# gcr_me16 register map
Registers are access not given, no defined reset value unless marked. A register's access mark holds for its fields unless they carry their own. Offsets are from the block's base; lines under a group give offsets from that group; [hi:lo] are bit positions; {n}, {i} and the like mark numbered series; 'fields as' and 'values as' point back to an identical list; <NAME> marks a mode.

## Memory map
0x40000000 GCR size 0x400 — Global Control Registers.

## GCR — Global Control Registers.
Base 0x40000000
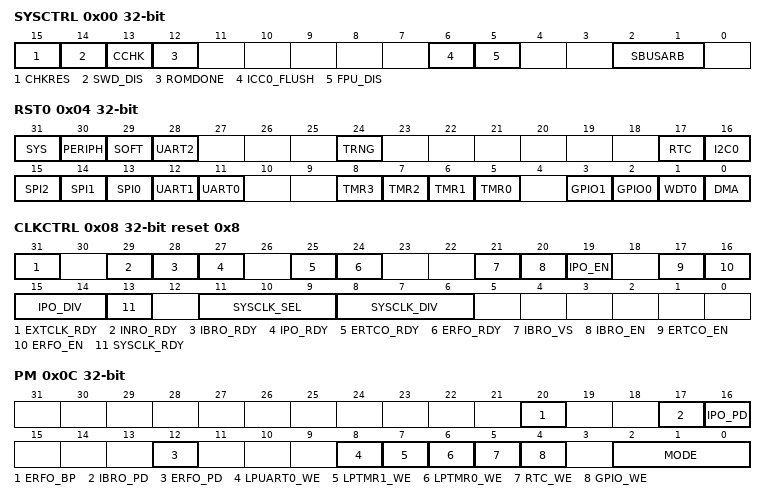
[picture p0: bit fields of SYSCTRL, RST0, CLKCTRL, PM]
0x00 SYSCTRL — System Control.
  [15] CHKRES — ROM Checksum Result. This bit is only valid when CHKRD=1.
    0=pass (ROM Checksum Correct.); 1=fail (ROM Checksum Fail.)
  [14] SWD_DIS — Serial Wire Debug Disable. This bit is used to disable the serial wire debug interface This bit is only writeable if (FMV lock word is not programmed) or if (ICE lock word is not programmed and the ROM_DONE bit is not set)
  [13] CCHK — Compute ROM Checksum. This bit is self-cleared when calculation is completed. Once set, software clearing this bit is ignored and the bit will remain set until the operation is completed.
    0=complete (No operation/complete.); 1=Start operation
  [12] ROMDONE — ROM_DONE status. Used to disable SWD interface during system initialization procedure
  [6] ICC0_FLUSH — Code Cache Flush. This bit is used to flush the code caches and the instruction buffer of the Cortex-M4.
    0=Normal Code Cache Operation; 1=flush (Code Caches and CPU instruction buffer are flushed)
  [5] FPU_DIS — Cortex M4 Floating Point Disable This bit is used to disable the floating-point unit of the Cortex-M4
  [2:1] SBUSARB — System bus abritration scheme. These bits are used to select between Fixed-burst abritration and Round-Robin scheme. The Round-Robin scheme is selected by default. These bits are reset by the system reset.
    0=fix (Fixed Burst abritration.); 1=Round-robin scheme
0x04 RST0 — Reset.
  [all] fields
    0=reset_done (Reset complete.); 1=busy (Starts Reset or indicates reset in progress.)
  [31] SYS — System Reset. Setting this bit to 1 resets the CPU core and all peripherals, including the watchdog timer.
  [30] PERIPH — Peripheral Reset. Setting this bit to 1 resets all peripherals. The CPU core, the watchdog timer, and all GPIO pins are unaffected by this reset.
  [29] SOFT — Soft Reset. Setting this bit to 1 resets everything except the CPU and the watchdog timer.
  [28] UART2 — UART2 Reset. Setting this bit to 1 resets all UART 2 blocks.
  [24] TRNG — TRNG Reset.
  [17] RTC — Real Time Clock Reset.
  [16] I2C0 — I2C0 Reset.
  [15] SPI2 — SPI2 Reset. Setting this bit to 1 resets all SPI 2 blocks.
  [14] SPI1 — SPI1 Reset. Setting this bit to 1 resets all SPI 1 blocks.
  [13] SPI0 — SPI0 Reset. Setting this bit to 1 resets all SPI 0 blocks.
  [12] UART1 — UART1 Reset. Setting this bit to 1 resets all UART 1 blocks.
  [11] UART0 — UART0 Reset. Setting this bit to 1 resets all UART 0 blocks.
  [n+5] TMR{n} (n=0..3) — Timer{n} Reset. Setting this bit to 1 resets Timer {n} blocks.
  [3] GPIO1 — GPIO1 Reset. Setting this bit to 1 resets GPIO1 pins to their default states.
  [2] GPIO0 — GPIO0 Reset. Setting this bit to 1 resets GPIO0 pins to their default states.
  [1] WDT0 — Watchdog Timer Reset.
  [0] DMA — DMA Reset.
0x08 CLKCTRL reset 0x8 — Clock Control.
  [31] EXTCLK_RDY ro — External Clock (GPIO0[11] AF2)
    0=not (Is not Ready.); 1=ready (Is Ready.)
  [29] INRO_RDY ro — 8kHz Low Frequency Reference Clock Ready.
    0=not (Is not Ready.); 1=ready (Is Ready.)
  [28] IBRO_RDY ro — 8MHz HIRC Ready.
    0=not (Is not Ready.); 1=ready (Is Ready.)
  [27] IPO_RDY ro — 96MHz HIRC Ready.
    0=not (Is not Ready.); 1=ready (Is Ready.)
  [25] ERTCO_RDY ro — 32kHz Crystal Oscillator Ready
    0=not (Is not Ready.); 1=ready (Is Ready.)
  [24] ERFO_RDY ro — 32MHz Crystal Oscillator Ready
    0=not (Is not Ready.); 1=ready (Is Ready.)
  [21] IBRO_VS — 8MHz High Frequency Internal Reference Clock Voltage Select. This register bit is used to select the power supply to the HIRC8M.
    0=VCore Supply; 1=1V (Dedicated 1v regulated supply.)
  [20] IBRO_EN — 8MHz High Frequency Internal Reference Clock Enable.
    0=dis (Is Disabled.); 1=en (Is Enabled.)
  [19] IPO_EN — 96MHz High Frequency Internal Reference Clock Enable.
    0=dis (Is Disabled.); 1=en (Is Enabled.)
  [17] ERTCO_EN — 32kHz Crystal Oscillator Enable.
    0=dis (Is Disabled.); 1=en (Is Enabled.)
  [16] ERFO_EN — 32MHz Crystal Oscillator Enable.
    0=dis (Is Disabled.); 1=en (Is Enabled.)
  [15:14] IPO_DIV — Divides the HIRC96M clock before the system clock prescaler, will affect HIRC96M Autocalibration.
    0=div1 (divide clock by 1); 1=div2 (divide clock by 2); 2=div4 (divide clock by 4); 3=div8 (divide clock by 8)
  [13] SYSCLK_RDY ro — Clock Ready. This read only bit reflects whether the currently selected system clock source is running.
    0=busy (Switchover to the new clock source (as selected by CLKSEL) has not yet occurred.); 1=ready (System clock running from CLKSEL clock source.)
  [11:9] SYSCLK_SEL — Clock Source Select. This 3 bit field selects the source for the system clock.
    2=ERFO (32MHz Crystal is used for the system clock.); 3=INRO (80kHz LIRC is used for the system clock.); 4=IPO (The internal 96 MHz oscillator is used for the system clock.); 5=IBRO (The internal 8 MHz oscillator is used for the system clock.); 6=ERTCO (32kHz is used for the system clock.); 7=EXTCLK (External clock on gpio0 11.)
  [8:6] SYSCLK_DIV — Prescaler Select. This 3 bit field sets the system operating frequency by controlling the prescaler that divides the output of the PLL0.
    0=div1 (Divide by 1.); 1=div2 (Divide by 2.); 2=div4 (Divide by 4.); 3=div8 (Divide by 8.); 4=div16 (Divide by 16.); 5=div32 (Divide by 32.); 6=div64 (Divide by 64.); 7=div128 (Divide by 128.)
0x0C PM — Power Management.
  [20] ERFO_BP — 32MHz Oscillator Bypass
  [17] IBRO_PD — 8MHz power down. This bit selects 8MHz HIRC power state in DEEPSLEEP mode.
    0=active (Mode is Active.); 1=deepsleep (Powered down in DEEPSLEEP.)
  [16] IPO_PD — 96MHz power down. This bit selects 96MHz HIRC power state in DEEPSLEEP mode.
    values as IBRO_PD
  [12] ERFO_PD — 32MHz power down. This bit selects 32MHz Crystal power state in DEEPSLEEP mode.
    values as IBRO_PD
  [8] LPUART0_WE — LPUART3 Wake Up Enable. This bit enables LPUART3 as wakeup source.
    0=dis (Wake Up Disable.); 1=en (Wake Up Enable.)
  [7] LPTMR1_WE — TIMER5 Wake Up Enable. This bit enables TIMER5 as wakeup source.
    0=dis (Wake Up Disable.); 1=en (Wake Up Enable.)
  [6] LPTMR0_WE — TIMER4 Wake Up Enable. This bit enables TIMER4 as wakeup source.
    0=dis (Wake Up Disable.); 1=en (Wake Up Enable.)
  [5] RTC_WE — RTC Alarm Wake Up Enable. This bit enables RTC alarm as wakeup source. If enabled, the desired RTC alarm must be configured via the RTC control registers.
    0=dis (Wake Up Disable.); 1=en (Wake Up Enable.)
  [4] GPIO_WE — GPIO Wake Up Enable. This bit enables all GPIO pins as potential wakeup sources. Any GPIO configured for wakeup is capable of causing an exit from IDLE or STANDBY modes when this bit is set.
    0=dis (Wake Up Disable.); 1=en (Wake Up Enable.)
  [2:0] MODE — Operating Mode. This two bit field selects the current operating mode for the device. Note that code execution only occurs during ACTIVE mode.
    0=Active Mode; 3=Shutdown Mode; 4=Backup Mode
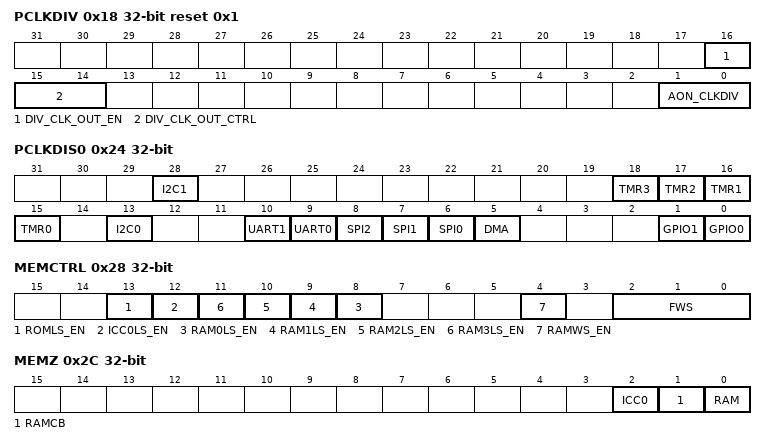
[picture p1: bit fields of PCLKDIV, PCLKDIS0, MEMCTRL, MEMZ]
0x18 PCLKDIV reset 0x1 — Peripheral Clock Divider.
  [16] DIV_CLK_OUT_EN — DIV_CLK_OUT Enable
  [15:14] DIV_CLK_OUT_CTRL — DIV_CLK_OUT Control
  [1:0] AON_CLKDIV — Always-ON (AON) domain Clock Divider. These bits define the AON domain clock divider
    0=div4; 1=div8; 2=div16; 3=div32
0x24 PCLKDIS0 — Peripheral Clock Disable.
  [all] fields
    0=en (enable it.); 1=dis (disable it.)
  [28] I2C1 — I2C 1 Disable.
  [n+15] TMR{n} (n=0..3) — Timer {n} Disable.
  [13] I2C0 — I2C 0 Disable.
  [10] UART1 — UART 1 Disable.
  [9] UART0 — UART 0 Disable.
  [8] SPI2 — SPI 2 Disable.
  [7] SPI1 — SPI 1 Disable.
  [6] SPI0 — SPI 0 Disable.
  [5] DMA — DMA Disable.
  [1] GPIO1 — GPIO1 Disable.
  [0] GPIO0 — GPIO0 Disable.
0x28 MEMCTRL — Memory Clock Control Register.
  [13] ROMLS_EN — ROM Light Sleep Mode.
    0=active (RAM is active.); 1=light_sleep (RAM is in Light Sleep mode.)
  [12] ICC0LS_EN — ICache RAM Light Sleep Mode.
    values as ROMLS_EN
  [n+8] RAM{n}LS_EN (n=0..3) — System RAM {n} Light Sleep Mode.
    values as ROMLS_EN
  [4] RAMWS_EN — System RAM Wait State enable
  [2:0] FWS — Flash Wait State. These bits define the number of wait-state cycles per Flash data read access. Minimum wait state is 2.
0x2C MEMZ — Memory Zeroize Control.
  [all] fields
    0=nop (No operation/complete.); 1=Start operation
  [2] ICC0 — Instruction Cache.
  [1] RAMCB — System RAM check bit zeroization.
  [0] RAM — System RAM Block.
0x40 SYSST — System Status Register.
  [0] ICELOCK — ARM ICE Lock Status.
    0=unlocked (ICE is unlocked.); 1=locked (ICE is locked.)
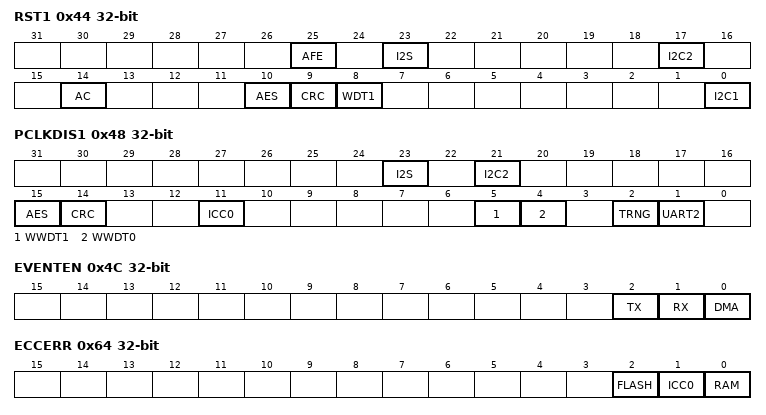
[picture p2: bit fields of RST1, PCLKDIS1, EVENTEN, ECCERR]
0x44 RST1 — Reset 1.
  [all] fields
    on read: 0=reset_done (Reset complete.); 1=busy (Starts reset or indicates reset in progress.)
  [25] AFE — AFE Reset.
  [23] I2S — I2S Reset.
  [17] I2C2 — I2C2 Reset.
  [14] AC — AC Reset.
  [10] AES — AES Reset.
  [9] CRC — CRC Reset.
  [8] WDT1 — WDT1 Reset.
  [0] I2C1 — I2C1 Reset.
0x48 PCLKDIS1 — Peripheral Clock Disable.
  [all] fields
    0=en (Enable.); 1=dis (Disable.)
  [23] I2S — I2S Clock Disable.
  [21] I2C2 — I2C2 Disable.
  [15] AES — AES Disable.
  [14] CRC — CRC Disable.
  [11] ICC0 — ICACHE Disable.
  [5] WWDT1 — WDT1 Disable.
  [4] WWDT0 — WDT0 Disable.
  [2] TRNG — TRNG Disable.
  [1] UART2 — UART2 Disable.
0x4C EVENTEN — Event Enable Register.
  [2] TX — Enable TXEV pin event. When this bit is set, TXEV event from the CPU is output to GPIO[21].
  [1] RX — Enable RXEV pin event. When this bit is set, a logic high of GPIO0[20] will cause an RXEV event to wake the CPU from WFE sleep mode.
  [0] DMA — Enable DMA event. When this bit is set, a DMA event will cause an RXEV event to wake the CPU from WFE sleep mode.
0x50 REVISION ro
  [15:0] REVISION — Manufacturer Chip Revision.
0x54 SYSIE — System Status Interrupt Enable Register.
  [0] ICEUNLOCK — ARM ICE Unlock Interrupt Enable.
    0=dis (disabled.); 1=en (enabled.)
0x64 ECCERR — ECC Error Register
  [2] FLASH — ECC Flash Error Flag. Write 1 to clear.
  [1] ICC0 — ECC Icache Error Flag. Write 1 to clear.
  [0] RAM — ECC System RAM0 Error Flag. Write 1 to clear.
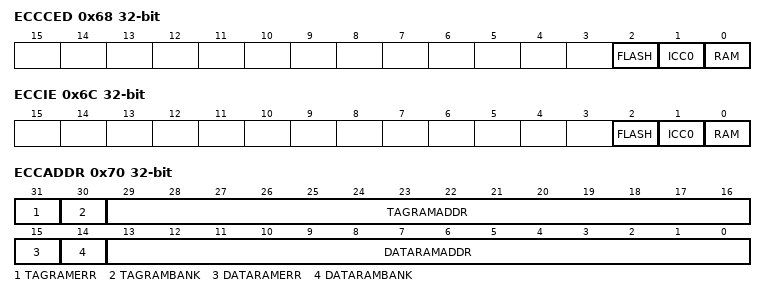
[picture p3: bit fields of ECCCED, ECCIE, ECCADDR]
0x68 ECCCED — ECC Not Double Error Detect Register
  [2] FLASH — ECC Flash0 Not Double Error Detect. Write 1 to clear.
  [1] ICC0 — ECC Icache Not Double Error Detect. Write 1 to clear.
  [0] RAM — ECC System RAM0 Error Flag. Write 1 to clear.
0x6C ECCIE — ECC IRQ Enable Register
  [2] FLASH — ECC Flash0 NError Interrup Enable
  [1] ICC0 — ECC Icache0 Error Interrup Enable
  [0] RAM — ECC System RAM0 Error Interrup Enable
0x70 ECCADDR — ECC Error Address Register
  [31] TAGRAMERR — ECC Error Address/TAG RAM Error.
  [30] TAGRAMBANK — ECC Error Address/TAG RAM Error Bank.
  [29:16] TAGRAMADDR — ECC Error Address/TAG RAM Error Address.
  [15] DATARAMERR — ECC Error Address/DATA RAM Error Address.
  [14] DATARAMBANK — ECC Error Address/DATA RAM Error Bank.
  [13:0] DATARAMADDR — ECC Error Address/TAG RAM Error Address.
